# f29h85x_cpu3_ipc_send_regs register map
Vendor: Texas Instruments
Peripheral module from a debugger description file (folder C29).
Registers are 32-bit, read-write, no defined reset value unless marked. A register's access mark holds for its fields unless they carry their own. Offsets are as the file gives them; lines under a group give offsets from that group; [hi:lo] are bit positions; {n}, {i} and the like mark numbered series; 'fields as' and 'values as' point back to an identical list; <NAME> marks a mode.

## CPU3_IPC_SEND_REGS — CPU3 IPC SEND Registers
{0x0+0x800*i} CPU3_IPC_SEND_REGS_RegisterFile0[{i}] (i=0..3) group
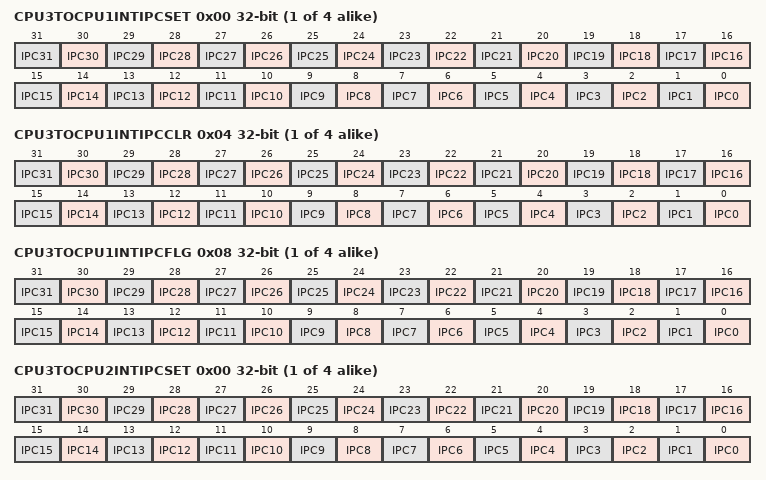
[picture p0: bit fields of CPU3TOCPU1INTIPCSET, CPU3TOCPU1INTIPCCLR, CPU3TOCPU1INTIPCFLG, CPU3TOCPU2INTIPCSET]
  0x00 CPU3TOCPU1INTIPCSET
    [n] IPC{n} (n=0..31) — Set Remote IPC{n} Flag
  0x04 CPU3TOCPU1INTIPCCLR
    [n] IPC{n} (n=0..31) — Clear CPU3TOCPU1IPCFLG.IPC{n} Flag
  0x08 CPU3TOCPU1INTIPCFLG ro
    [n] IPC{n} (n=0..31) — CPU3 to CPU1 IPC{n} Flag Status
  0x10 CPU3TOCPU1INTIPCSENDCOM
    [31:0] COMMAND — CPU3 to CPU1 IPC Command
  0x14 CPU3TOCPU1INTIPCSENDADDR
    [31:0] ADDRESS — CPU3 to CPU1 IPC Address
  0x18 CPU3TOCPU1INTIPCSENDDATA
    [31:0] DATA — CPU3 to CPU1 IPC Data
  0x1C CPU1TOCPU3INTREMOTEREPLY ro
    [31:0] REPLY — Refelects the state of CPU1TOCPU3INT IPCREPLY register
{0x2000+0x800*i} CPU3_IPC_SEND_REGS_RegisterFile1[{i}] (i=0..3) group
  0x00 CPU3TOCPU2INTIPCSET
    [n] IPC{n} (n=0..31) — Set Remote IPC{n} Flag
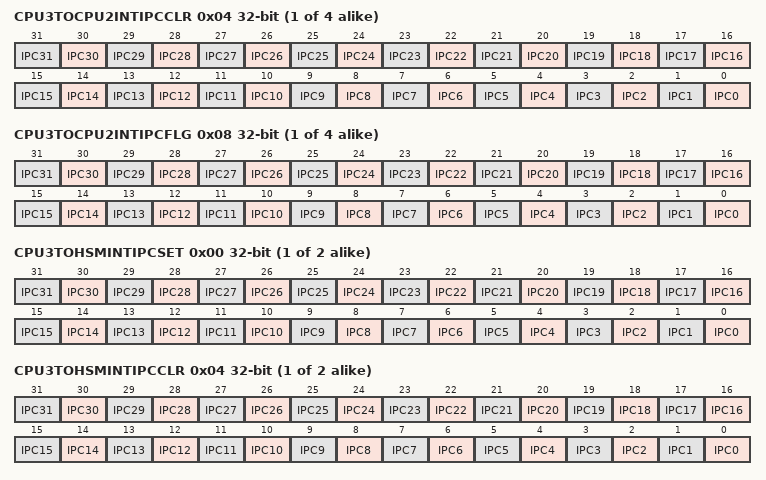
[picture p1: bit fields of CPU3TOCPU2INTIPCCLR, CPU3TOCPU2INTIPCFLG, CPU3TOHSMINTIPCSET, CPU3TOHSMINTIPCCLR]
  0x04 CPU3TOCPU2INTIPCCLR
    [n] IPC{n} (n=0..31) — Clear CPU3TOCPU2IPCFLG.IPC{n} Flag
  0x08 CPU3TOCPU2INTIPCFLG ro
    [n] IPC{n} (n=0..31) — CPU3 to CPU2 IPC{n} Flag Status
  0x10 CPU3TOCPU2INTIPCSENDCOM
    [31:0] COMMAND — CPU3 to CPU2 IPC Command
  0x14 CPU3TOCPU2INTIPCSENDADDR
    [31:0] ADDRESS — CPU3 to CPU2 IPC Address
  0x18 CPU3TOCPU2INTIPCSENDDATA
    [31:0] DATA — CPU3 to CPU2 IPC Data
  0x1C CPU2TOCPU3INTREMOTEREPLY ro
    [31:0] REPLY — Refelects the state of CPU2TOCPU3INT IPCREPLY register
{0x6000+0x1000*i} CPU3_IPC_SEND_REGS_RegisterFile2[{i}] (i=0..1) group
  0x00 CPU3TOHSMINTIPCSET
    [n] IPC{n} (n=0..31) — Set Remote IPC{n} Flag
  0x04 CPU3TOHSMINTIPCCLR
    [n] IPC{n} (n=0..31) — Clear CPU3TOHSMIPCFLG.IPC{n} Flag
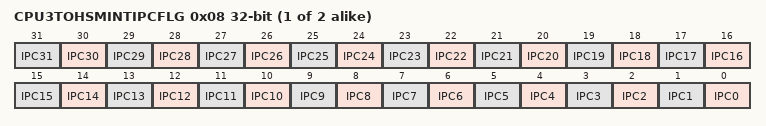
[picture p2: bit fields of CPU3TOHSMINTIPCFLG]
  0x08 CPU3TOHSMINTIPCFLG ro
    [n] IPC{n} (n=0..31) — HSM to CPU3 IPC{n} Flag Status
